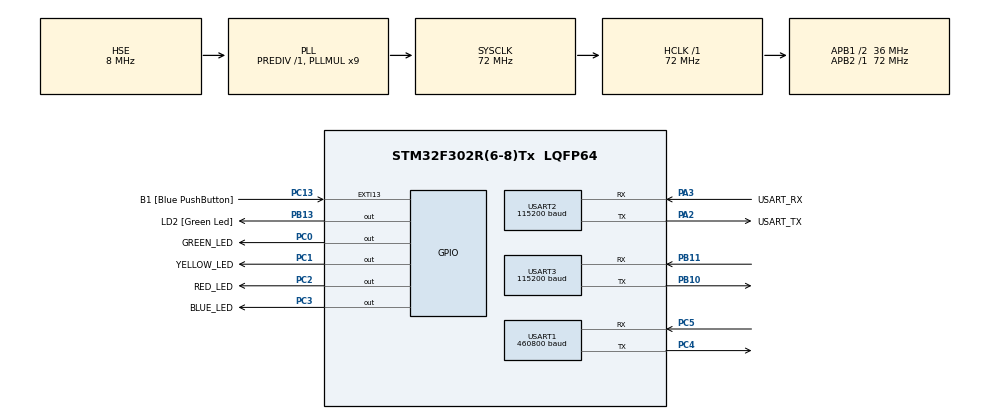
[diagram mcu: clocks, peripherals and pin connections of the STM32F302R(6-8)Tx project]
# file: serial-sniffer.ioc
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Dma.Request0=USART1_TX
Dma.Request1=USART1_RX
Dma.USART1_RX.1.Direction=DMA_PERIPH_TO_MEMORY
Dma.USART1_RX.1.Instance=DMA1_Channel5
Dma.USART1_RX.1.MemDataAlignment=DMA_MDATAALIGN_BYTE
Dma.USART1_RX.1.MemInc=DMA_MINC_ENABLE
Dma.USART1_RX.1.Mode=DMA_NORMAL
Dma.USART1_RX.1.PeriphDataAlignment=DMA_PDATAALIGN_BYTE
Dma.USART1_RX.1.PeriphInc=DMA_PINC_DISABLE
Dma.USART1_RX.1.Priority=DMA_PRIORITY_LOW
Dma.USART1_TX.0.Direction=DMA_MEMORY_TO_PERIPH
Dma.USART1_TX.0.Instance=DMA1_Channel4
Dma.USART1_TX.0.MemDataAlignment=DMA_MDATAALIGN_BYTE
Dma.USART1_TX.0.MemInc=DMA_MINC_ENABLE
Dma.USART1_TX.0.Mode=DMA_NORMAL
Dma.USART1_TX.0.PeriphDataAlignment=DMA_PDATAALIGN_BYTE
Dma.USART1_TX.0.PeriphInc=DMA_PINC_DISABLE
Dma.USART1_TX.0.Priority=DMA_PRIORITY_MEDIUM
Mcu.Family=STM32F3
Mcu.Name=STM32F302R(6-8)Tx
Mcu.Package=LQFP64
NVIC.DMA1_Channel4_IRQn=true\:0\:0\:false\:false\:true\:false\:true\:true
NVIC.DMA1_Channel5_IRQn=true\:0\:0\:false\:false\:true\:false\:true\:true
NVIC.PriorityGroup=NVIC_PRIORITYGROUP_0
NVIC.TIM6_DAC_IRQn=true\:0\:0\:false\:false\:true\:true\:true\:true
NVIC.USART1_IRQn=true\:0\:0\:false\:false\:true\:true\:true\:true
NVIC.USART2_IRQn=true\:0\:0\:false\:false\:true\:true\:true\:true
NVIC.USART3_IRQn=true\:0\:0\:false\:false\:true\:true\:true\:true
PA13.GPIO_Label=TMS
PA13.Mode=Serial_Wire
PA13.Signal=SYS_JTMS-SWDIO
PA14.GPIO_Label=TCK
PA14.Mode=Serial_Wire
PA14.Signal=SYS_JTCK-SWCLK
PA2.GPIO_Label=USART_TX
PA2.GPIO_Mode=GPIO_MODE_AF_PP
PA2.GPIO_PuPd=GPIO_NOPULL
PA2.GPIO_Speed=GPIO_SPEED_FREQ_LOW
PA2.Mode=Asynchronous
PA2.Signal=USART2_TX
PA3.GPIO_Label=USART_RX
PA3.GPIO_Mode=GPIO_MODE_AF_PP
PA3.GPIO_PuPd=GPIO_NOPULL
PA3.GPIO_Speed=GPIO_SPEED_FREQ_LOW
PA3.Mode=Asynchronous
PA3.Signal=USART2_RX
PB10.Mode=Asynchronous
PB10.Signal=USART3_TX
PB11.Mode=Asynchronous
PB11.Signal=USART3_RX
PB13.GPIO_Label=LD2 [Green Led]
PB13.Signal=GPIO_Output
PB3.GPIO_Label=SWO
PB3.Mode=Trace_Asynchronous_SW
PB3.Signal=SYS_JTDO-TRACESWO
PC0.GPIO_Label=GREEN_LED
PC0.GPIO_Speed=GPIO_SPEED_FREQ_LOW
PC0.Signal=GPIO_Output
PC1.GPIO_Label=YELLOW_LED
PC1.GPIO_Speed=GPIO_SPEED_FREQ_LOW
PC1.Signal=GPIO_Output
PC13.GPIO_Label=B1 [Blue PushButton]
PC13.GPIO_ModeDefaultEXTI=GPIO_MODE_IT_FALLING
PC13.Signal=GPXTI13
PC14\ -\ OSC32_IN.Mode=LSE-External-Oscillator
PC14\ -\ OSC32_IN.Signal=RCC_OSC32_IN
PC15\ -\ OSC32_OUT.Mode=LSE-External-Oscillator
PC15\ -\ OSC32_OUT.Signal=RCC_OSC32_OUT
PC2.GPIO_Label=RED_LED
PC2.GPIO_Speed=GPIO_SPEED_FREQ_LOW
PC2.Signal=GPIO_Output
PC3.GPIO_Label=BLUE_LED
PC3.GPIO_Speed=GPIO_SPEED_FREQ_LOW
PC3.Signal=GPIO_Output
PC4.Mode=Asynchronous
PC4.Signal=USART1_TX
PC5.Mode=Asynchronous
PC5.Signal=USART1_RX
PF0-OSC_IN.Mode=HSE-External-Clock-Source
PF0-OSC_IN.Signal=RCC_OSC_IN
PF1-OSC_OUT.Signal=RCC_OSC_OUT
ProjectManager.HeapSize=0x200
ProjectManager.StackSize=0x400
ProjectManager.TargetToolchain=STM32CubeIDE
RCC.AHBFreq_Value=72000000
RCC.APB1CLKDivider=RCC_HCLK_DIV2
RCC.APB1Freq_Value=36000000
RCC.APB1TimFreq_Value=72000000
RCC.APB2Freq_Value=72000000
RCC.APB2TimFreq_Value=72000000
RCC.CortexFreq_Value=72000000
RCC.HCLKFreq_Value=72000000
RCC.HSE_VALUE=8000000
RCC.HSI_VALUE=8000000
RCC.PLLM=8
RCC.PLLMUL=RCC_PLL_MUL9
RCC.PLLN=336
RCC.PLLP=RCC_PLLP_DIV4
RCC.PLLQ=7
RCC.PLLSourceVirtual=RCC_PLLSOURCE_HSE
RCC.SYSCLKFreq_VALUE=72000000
RCC.SYSCLKSourceVirtual=RCC_SYSCLKSOURCE_PLLCLK
RCC.USBFreq_Value=72000000
TIM6.AutoReloadPreload=TIM_AUTORELOAD_PRELOAD_ENABLE
TIM6.Period=50000
TIM6.Prescaler=143
USART1.BaudRate=460800
USART1.VirtualMode-Asynchronous=VM_ASYNC
USART2.BaudRate=115200
USART2.VirtualMode-Asynchronous=VM_ASYNC
USART3.BaudRate=115200
USART3.VirtualMode-Asynchronous=VM_ASYNC
VP_TIM6_VS_ClockSourceINT.Mode=Enable_Timer
board=NUCLEO-F302R8

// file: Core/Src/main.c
/* USER CODE BEGIN Header */
/**
  ******************************************************************************
  * @file           : main.c
  * @brief          : Main program body
  ******************************************************************************
  * @attention
  *
  * Copyright (c) 2022 STMicroelectronics.
  * All rights reserved.
  *
  * This software is licensed under terms that can be found in the LICENSE file
  * in the root directory of this software component.
  * If no LICENSE file comes with this software, it is provided AS-IS.
  *
  ******************************************************************************
  */
/* USER CODE END Header */
#include "main.h"

/* USER CODE BEGIN Includes */
#include "mainApp.h"
/* USER CODE END Includes */

TIM_HandleTypeDef htim6;

UART_HandleTypeDef huart1;
UART_HandleTypeDef huart2;
UART_HandleTypeDef huart3;
DMA_HandleTypeDef hdma_usart1_tx;
DMA_HandleTypeDef hdma_usart1_rx;

void SystemClock_Config(void);
static void MX_GPIO_Init(void);
static void MX_DMA_Init(void);
static void MX_USART2_UART_Init(void);
static void MX_USART1_UART_Init(void);
static void MX_USART3_UART_Init(void);
static void MX_TIM6_Init(void);

int main(void)
{

  /* MCU Configuration--------------------------------------------------------*/

  /* Reset of all peripherals, Initializes the Flash interface and the Systick. */
  HAL_Init();

  /* Configure the system clock */
  SystemClock_Config();

  /* Initialize all configured peripherals */
  MX_GPIO_Init();
  MX_DMA_Init();
  MX_USART2_UART_Init();
  MX_USART1_UART_Init();
  MX_USART3_UART_Init();
  MX_TIM6_Init();

  /* Infinite loop */
  /* USER CODE BEGIN WHILE */
  mainApp();
  while (1)
  {
    /* USER CODE END WHILE */

  }
}

void SystemClock_Config(void)
{
  RCC_OscInitTypeDef RCC_OscInitStruct = {0};
  RCC_ClkInitTypeDef RCC_ClkInitStruct = {0};
  RCC_PeriphCLKInitTypeDef PeriphClkInit = {0};

  /** Initializes the RCC Oscillators according to the specified parameters
  * in the RCC_OscInitTypeDef structure.
  */
  RCC_OscInitStruct.OscillatorType = RCC_OSCILLATORTYPE_HSE;
  RCC_OscInitStruct.HSEState = RCC_HSE_BYPASS;
  RCC_OscInitStruct.HSEPredivValue = RCC_HSE_PREDIV_DIV1;
  RCC_OscInitStruct.HSIState = RCC_HSI_ON;
  RCC_OscInitStruct.PLL.PLLState = RCC_PLL_ON;
  RCC_OscInitStruct.PLL.PLLSource = RCC_PLLSOURCE_HSE;
  RCC_OscInitStruct.PLL.PLLMUL = RCC_PLL_MUL9;
  if (HAL_RCC_OscConfig(&RCC_OscInitStruct) != HAL_OK)
  {
    Error_Handler();
  }

  /** Initializes the CPU, AHB and APB buses clocks
  */
  RCC_ClkInitStruct.ClockType = RCC_CLOCKTYPE_HCLK|RCC_CLOCKTYPE_SYSCLK
                              |RCC_CLOCKTYPE_PCLK1|RCC_CLOCKTYPE_PCLK2;
  RCC_ClkInitStruct.SYSCLKSource = RCC_SYSCLKSOURCE_PLLCLK;
  RCC_ClkInitStruct.AHBCLKDivider = RCC_SYSCLK_DIV1;
  RCC_ClkInitStruct.APB1CLKDivider = RCC_HCLK_DIV2;
  RCC_ClkInitStruct.APB2CLKDivider = RCC_HCLK_DIV1;

  if (HAL_RCC_ClockConfig(&RCC_ClkInitStruct, FLASH_LATENCY_2) != HAL_OK)
  {
    Error_Handler();
  }
  PeriphClkInit.PeriphClockSelection = RCC_PERIPHCLK_USART1;
  PeriphClkInit.Usart1ClockSelection = RCC_USART1CLKSOURCE_PCLK1;
  if (HAL_RCCEx_PeriphCLKConfig(&PeriphClkInit) != HAL_OK)
  {
    Error_Handler();
  }
}

static void MX_TIM6_Init(void)
{

  TIM_MasterConfigTypeDef sMasterConfig = {0};

  htim6.Instance = TIM6;
  htim6.Init.Prescaler = 143;
  htim6.Init.CounterMode = TIM_COUNTERMODE_UP;
  htim6.Init.Period = 50000;
  htim6.Init.AutoReloadPreload = TIM_AUTORELOAD_PRELOAD_ENABLE;
  if (HAL_TIM_Base_Init(&htim6) != HAL_OK)
  {
    Error_Handler();
  }
  sMasterConfig.MasterOutputTrigger = TIM_TRGO_RESET;
  sMasterConfig.MasterSlaveMode = TIM_MASTERSLAVEMODE_DISABLE;
  if (HAL_TIMEx_MasterConfigSynchronization(&htim6, &sMasterConfig) != HAL_OK)
  {
    Error_Handler();
  }

}

static void MX_USART1_UART_Init(void)
{

  huart1.Instance = USART1;
  huart1.Init.BaudRate = 460800;
  huart1.Init.WordLength = UART_WORDLENGTH_8B;
  huart1.Init.StopBits = UART_STOPBITS_1;
  huart1.Init.Parity = UART_PARITY_NONE;
  huart1.Init.Mode = UART_MODE_TX_RX;
  huart1.Init.HwFlowCtl = UART_HWCONTROL_NONE;
  huart1.Init.OverSampling = UART_OVERSAMPLING_16;
  huart1.Init.OneBitSampling = UART_ONE_BIT_SAMPLE_DISABLE;
  huart1.AdvancedInit.AdvFeatureInit = UART_ADVFEATURE_NO_INIT;
  if (HAL_UART_Init(&huart1) != HAL_OK)
  {
    Error_Handler();
  }

}

static void MX_USART2_UART_Init(void)
{

  huart2.Instance = USART2;
  huart2.Init.BaudRate = 115200;
  huart2.Init.WordLength = UART_WORDLENGTH_8B;
  huart2.Init.StopBits = UART_STOPBITS_1;
  huart2.Init.Parity = UART_PARITY_NONE;
  huart2.Init.Mode = UART_MODE_TX_RX;
  huart2.Init.HwFlowCtl = UART_HWCONTROL_NONE;
  huart2.Init.OverSampling = UART_OVERSAMPLING_16;
  huart2.Init.OneBitSampling = UART_ONE_BIT_SAMPLE_DISABLE;
  huart2.AdvancedInit.AdvFeatureInit = UART_ADVFEATURE_NO_INIT;
  if (HAL_UART_Init(&huart2) != HAL_OK)
  {
    Error_Handler();
  }

}

static void MX_USART3_UART_Init(void)
{

  huart3.Instance = USART3;
  huart3.Init.BaudRate = 115200;
  huart3.Init.WordLength = UART_WORDLENGTH_8B;
  huart3.Init.StopBits = UART_STOPBITS_1;
  huart3.Init.Parity = UART_PARITY_NONE;
  huart3.Init.Mode = UART_MODE_TX_RX;
  huart3.Init.HwFlowCtl = UART_HWCONTROL_NONE;
  huart3.Init.OverSampling = UART_OVERSAMPLING_16;
  huart3.Init.OneBitSampling = UART_ONE_BIT_SAMPLE_DISABLE;
  huart3.AdvancedInit.AdvFeatureInit = UART_ADVFEATURE_NO_INIT;
  if (HAL_UART_Init(&huart3) != HAL_OK)
  {
    Error_Handler();
  }

}

static void MX_DMA_Init(void)
{

  /* DMA controller clock enable */
  __HAL_RCC_DMA1_CLK_ENABLE();

  /* DMA interrupt init */
  /* DMA1_Channel4_IRQn interrupt configuration */
  HAL_NVIC_SetPriority(DMA1_Channel4_IRQn, 0, 0);
  HAL_NVIC_EnableIRQ(DMA1_Channel4_IRQn);
  /* DMA1_Channel5_IRQn interrupt configuration */
  HAL_NVIC_SetPriority(DMA1_Channel5_IRQn, 0, 0);
  HAL_NVIC_EnableIRQ(DMA1_Channel5_IRQn);

}

static void MX_GPIO_Init(void)
{
  GPIO_InitTypeDef GPIO_InitStruct = {0};

  /* GPIO Ports Clock Enable */
  __HAL_RCC_GPIOC_CLK_ENABLE();
  __HAL_RCC_GPIOF_CLK_ENABLE();
  __HAL_RCC_GPIOA_CLK_ENABLE();
  __HAL_RCC_GPIOB_CLK_ENABLE();

  /*Configure GPIO pin Output Level */
  HAL_GPIO_WritePin(GPIOC, GREEN_LED_Pin|YELLOW_LED_Pin|RED_LED_Pin|BLUE_LED_Pin, GPIO_PIN_RESET);

  /*Configure GPIO pin Output Level */
  HAL_GPIO_WritePin(LD2_GPIO_Port, LD2_Pin, GPIO_PIN_RESET);

  /*Configure GPIO pin : B1_Pin */
  GPIO_InitStruct.Pin = B1_Pin;
  GPIO_InitStruct.Mode = GPIO_MODE_IT_FALLING;
  GPIO_InitStruct.Pull = GPIO_NOPULL;
  HAL_GPIO_Init(B1_GPIO_Port, &GPIO_InitStruct);

  /*Configure GPIO pins : GREEN_LED_Pin YELLOW_LED_Pin RED_LED_Pin BLUE_LED_Pin */
  GPIO_InitStruct.Pin = GREEN_LED_Pin|YELLOW_LED_Pin|RED_LED_Pin|BLUE_LED_Pin;
  GPIO_InitStruct.Mode = GPIO_MODE_OUTPUT_PP;
  GPIO_InitStruct.Pull = GPIO_NOPULL;
  GPIO_InitStruct.Speed = GPIO_SPEED_FREQ_LOW;
  HAL_GPIO_Init(GPIOC, &GPIO_InitStruct);

  /*Configure GPIO pin : LD2_Pin */
  GPIO_InitStruct.Pin = LD2_Pin;
  GPIO_InitStruct.Mode = GPIO_MODE_OUTPUT_PP;
  GPIO_InitStruct.Pull = GPIO_NOPULL;
  GPIO_InitStruct.Speed = GPIO_SPEED_FREQ_LOW;
  HAL_GPIO_Init(LD2_GPIO_Port, &GPIO_InitStruct);

}

void Error_Handler(void)
{
  __disable_irq();
  while (1)
  {
  }
}
